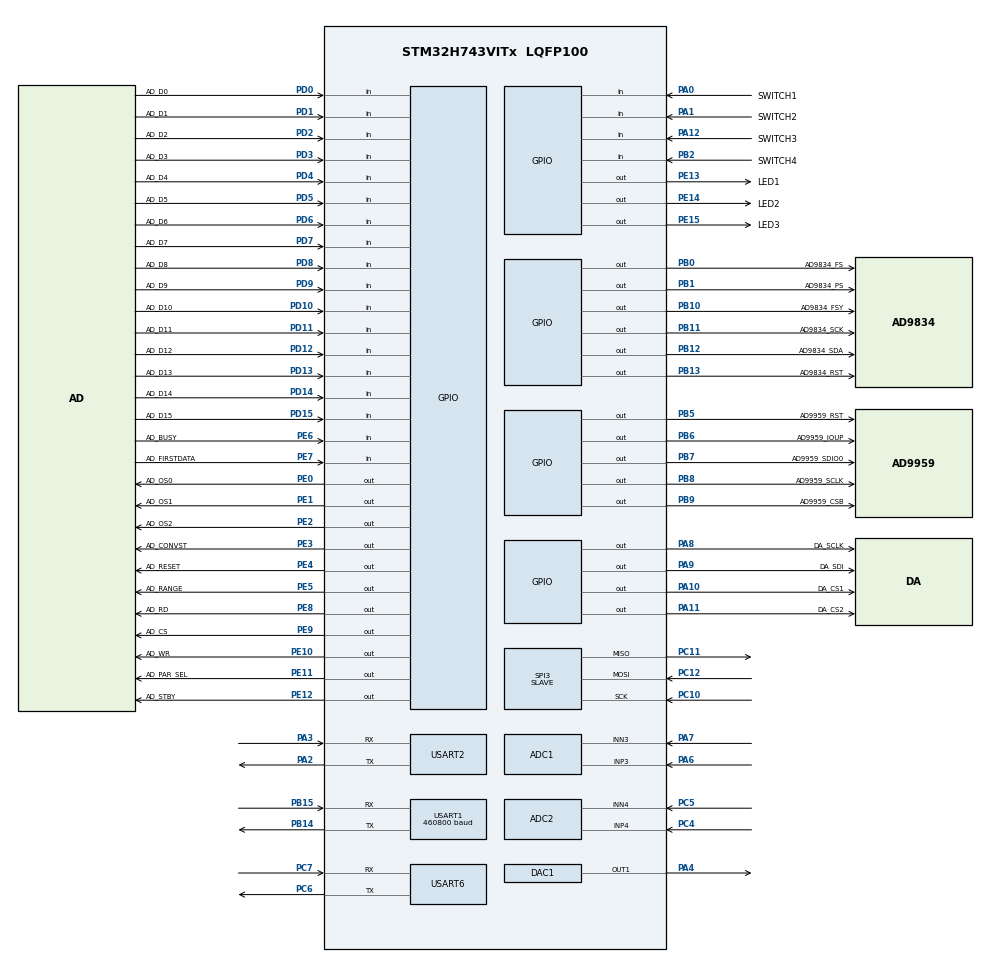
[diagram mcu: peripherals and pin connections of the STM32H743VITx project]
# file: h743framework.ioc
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ADC1.Channel-0\#ChannelRegularConversion=ADC_CHANNEL_3
ADC1.ClockPrescaler=ADC_CLOCK_ASYNC_DIV2
ADC1.NbrOfConversionFlag=1
ADC1.OffsetNumber-0\#ChannelRegularConversion=ADC_OFFSET_NONE
ADC1.OffsetSignedSaturation-0\#ChannelRegularConversion=DISABLE
ADC1.Rank-0\#ChannelRegularConversion=1
ADC1.SamplingTime-0\#ChannelRegularConversion=ADC_SAMPLETIME_1CYCLE_5
ADC1.SingleDiff-0\#ChannelRegularConversion=ADC_DIFFERENTIAL_ENDED
ADC1.master=1
ADC2.Channel-0\#ChannelRegularConversion=ADC_CHANNEL_4
ADC2.ClockPrescaler=ADC_CLOCK_ASYNC_DIV2
ADC2.NbrOfConversionFlag=1
ADC2.OffsetNumber-0\#ChannelRegularConversion=ADC_OFFSET_NONE
ADC2.OffsetSignedSaturation-0\#ChannelRegularConversion=DISABLE
ADC2.Rank-0\#ChannelRegularConversion=1
ADC2.SamplingTime-0\#ChannelRegularConversion=ADC_SAMPLETIME_1CYCLE_5
ADC2.SingleDiff-0\#ChannelRegularConversion=ADC_DIFFERENTIAL_ENDED
CORTEX_M7.CPU_DCache=Enabled
CORTEX_M7.CPU_ICache=Enabled
DAC1.DAC_Channel-DAC_OUT1=DAC_CHANNEL_1
Dma.Request0=SPI3_RX
Dma.SPI3_RX.0.Direction=DMA_PERIPH_TO_MEMORY
Dma.SPI3_RX.0.EventEnable=DISABLE
Dma.SPI3_RX.0.FIFOMode=DMA_FIFOMODE_DISABLE
Dma.SPI3_RX.0.Instance=DMA1_Stream0
Dma.SPI3_RX.0.MemDataAlignment=DMA_MDATAALIGN_HALFWORD
Dma.SPI3_RX.0.MemInc=DMA_MINC_ENABLE
Dma.SPI3_RX.0.Mode=DMA_CIRCULAR
Dma.SPI3_RX.0.PeriphDataAlignment=DMA_PDATAALIGN_HALFWORD
Dma.SPI3_RX.0.PeriphInc=DMA_PINC_DISABLE
Dma.SPI3_RX.0.Polarity=HAL_DMAMUX_REQ_GEN_RISING
Dma.SPI3_RX.0.Priority=DMA_PRIORITY_LOW
Dma.SPI3_RX.0.RequestNumber=1
Dma.SPI3_RX.0.SignalID=NONE
Dma.SPI3_RX.0.SyncEnable=DISABLE
Dma.SPI3_RX.0.SyncPolarity=HAL_DMAMUX_SYNC_NO_EVENT
Dma.SPI3_RX.0.SyncRequestNumber=1
Dma.SPI3_RX.0.SyncSignalID=NONE
Mcu.Family=STM32H7
Mcu.Name=STM32H743VITx
Mcu.Package=LQFP100
NVIC.DMA1_Stream0_IRQn=true\:0\:0\:false\:false\:true\:false\:true\:true
NVIC.PriorityGroup=NVIC_PRIORITYGROUP_4
NVIC.SPI3_IRQn=true\:0\:0\:false\:false\:true\:false\:true\:true
NVIC.TIM3_IRQn=true\:0\:0\:false\:false\:true\:true\:true\:true
NVIC.TIM4_IRQn=true\:0\:0\:false\:false\:true\:true\:true\:true
NVIC.TIM5_IRQn=true\:0\:0\:false\:false\:true\:true\:true\:true
NVIC.TIM6_DAC_IRQn=true\:0\:0\:false\:false\:true\:true\:true\:true
NVIC.TIM7_IRQn=true\:0\:0\:false\:false\:true\:true\:true\:true
NVIC.USART1_IRQn=true\:0\:0\:false\:false\:true\:true\:true\:true
NVIC.USART2_IRQn=true\:0\:0\:false\:false\:true\:true\:true\:true
NVIC.USART6_IRQn=true\:0\:0\:false\:false\:true\:true\:true\:true
PA0.GPIO_Label=SWITCH1
PA0.Signal=GPIO_Input
PA1.GPIO_Label=SWITCH2
PA1.Signal=GPIO_Input
PA10.GPIO_Label=DA_CS1
PA10.GPIO_Speed=GPIO_SPEED_FREQ_HIGH
PA10.Signal=GPIO_Output
PA11.GPIO_Label=DA_CS2
PA11.GPIO_Speed=GPIO_SPEED_FREQ_HIGH
PA11.Signal=GPIO_Output
PA12.GPIO_Label=SWITCH3
PA12.Signal=GPIO_Input
PA13\ (JTMS/SWDIO).Mode=JTAG_5_pins
PA13\ (JTMS/SWDIO).Signal=DEBUG_JTMS-SWDIO
PA14\ (JTCK/SWCLK).Mode=JTAG_5_pins
PA14\ (JTCK/SWCLK).Signal=DEBUG_JTCK-SWCLK
PA15\ (JTDI).Mode=JTAG_5_pins
PA15\ (JTDI).Signal=DEBUG_JTDI
PA2.Mode=Asynchronous
PA2.Signal=USART2_TX
PA3.Mode=Asynchronous
PA3.Signal=USART2_RX
PA4.Signal=COMP_DAC11_group
PA5.Signal=S_TIM2_CH1_ETR
PA6.Signal=ADCx_INP3
PA7.Signal=ADCx_INN3
PA8.GPIO_Label=DA_SCLK
PA8.GPIO_Speed=GPIO_SPEED_FREQ_HIGH
PA8.Signal=GPIO_Output
PA9.GPIO_Label=DA_SDI
PA9.GPIO_Speed=GPIO_SPEED_FREQ_HIGH
PA9.Signal=GPIO_Output
PB0.GPIO_Label=AD9834_FS
PB0.GPIO_Speed=GPIO_SPEED_FREQ_HIGH
PB0.Signal=GPIO_Output
PB1.GPIO_Label=AD9834_PS
PB1.GPIO_Speed=GPIO_SPEED_FREQ_HIGH
PB1.Signal=GPIO_Output
PB10.GPIO_Label=AD9834_FSY
PB10.GPIO_Speed=GPIO_SPEED_FREQ_HIGH
PB10.Signal=GPIO_Output
PB11.GPIO_Label=AD9834_SCK
PB11.GPIO_Speed=GPIO_SPEED_FREQ_HIGH
PB11.Signal=GPIO_Output
PB12.GPIO_Label=AD9834_SDA
PB12.GPIO_Speed=GPIO_SPEED_FREQ_HIGH
PB12.Signal=GPIO_Output
PB13.GPIO_Label=AD9834_RST
PB13.GPIO_Speed=GPIO_SPEED_FREQ_HIGH
PB13.Signal=GPIO_Output
PB14.Mode=Asynchronous
PB14.Signal=USART1_TX
PB15.Mode=Asynchronous
PB15.Signal=USART1_RX
PB2.GPIO_Label=SWITCH4
PB2.Signal=GPIO_Input
PB3\ (JTDO/TRACESWO).Mode=JTAG_5_pins
PB3\ (JTDO/TRACESWO).Signal=DEBUG_JTDO-SWO
PB4\ (NJTRST).Mode=JTAG_5_pins
PB4\ (NJTRST).Signal=DEBUG_JTRST
PB5.GPIO_Label=AD9959_RST
PB5.GPIO_Speed=GPIO_SPEED_FREQ_HIGH
PB5.Signal=GPIO_Output
PB6.GPIO_Label=AD9959_IOUP
PB6.GPIO_Speed=GPIO_SPEED_FREQ_HIGH
PB6.Signal=GPIO_Output
PB7.GPIO_Label=AD9959_SDIO0
PB7.GPIO_Speed=GPIO_SPEED_FREQ_HIGH
PB7.Signal=GPIO_Output
PB8.GPIO_Label=AD9959_SCLK
PB8.GPIO_Speed=GPIO_SPEED_FREQ_HIGH
PB8.Signal=GPIO_Output
PB9.GPIO_Label=AD9959_CSB
PB9.GPIO_Speed=GPIO_SPEED_FREQ_HIGH
PB9.Signal=GPIO_Output
PC10.Mode=Full_Duplex_Slave
PC10.Signal=SPI3_SCK
PC11.Mode=Full_Duplex_Slave
PC11.Signal=SPI3_MISO
PC12.Mode=Full_Duplex_Slave
PC12.Signal=SPI3_MOSI
PC4.Signal=ADCx_INP4
PC5.Signal=ADCx_INN4
PC6.Mode=Asynchronous
PC6.Signal=USART6_TX
PC7.Mode=Asynchronous
PC7.Signal=USART6_RX
PD0.GPIO_Label=AD_D0
PD0.Signal=GPIO_Input
PD1.GPIO_Label=AD_D1
PD1.Signal=GPIO_Input
PD10.GPIO_Label=AD_D10
PD10.Signal=GPIO_Input
PD11.GPIO_Label=AD_D11
PD11.Signal=GPIO_Input
PD12.GPIO_Label=AD_D12
PD12.Signal=GPIO_Input
PD13.GPIO_Label=AD_D13
PD13.Signal=GPIO_Input
PD14.GPIO_Label=AD_D14
PD14.Signal=GPIO_Input
PD15.GPIO_Label=AD_D15
PD15.Signal=GPIO_Input
PD2.GPIO_Label=AD_D2
PD2.Signal=GPIO_Input
PD3.GPIO_Label=AD_D3
PD3.Signal=GPIO_Input
PD4.GPIO_Label=AD_D4
PD4.Signal=GPIO_Input
PD5.GPIO_Label=AD_D5
PD5.Signal=GPIO_Input
PD6.GPIO_Label=AD_D6
PD6.Signal=GPIO_Input
PD7.GPIO_Label=AD_D7
PD7.Signal=GPIO_Input
PD8.GPIO_Label=AD_D8
PD8.Signal=GPIO_Input
PD9.GPIO_Label=AD_D9
PD9.Signal=GPIO_Input
PE0.GPIO_Label=AD_OS0
PE0.GPIO_Speed=GPIO_SPEED_FREQ_LOW
PE0.Signal=GPIO_Output
PE1.GPIO_Label=AD_OS1
PE1.GPIO_Speed=GPIO_SPEED_FREQ_LOW
PE1.Signal=GPIO_Output
PE10.GPIO_Label=AD_WR
PE10.GPIO_Speed=GPIO_SPEED_FREQ_HIGH
PE10.Signal=GPIO_Output
PE11.GPIO_Label=AD_PAR_SEL
PE11.GPIO_Speed=GPIO_SPEED_FREQ_LOW
PE11.Signal=GPIO_Output
PE12.GPIO_Label=AD_STBY
PE12.GPIO_Speed=GPIO_SPEED_FREQ_LOW
PE12.Signal=GPIO_Output
PE13.GPIO_Label=LED1
PE13.Signal=GPIO_Output
PE14.GPIO_Label=LED2
PE14.Signal=GPIO_Output
PE15.GPIO_Label=LED3
PE15.Signal=GPIO_Output
PE2.GPIO_Label=AD_OS2
PE2.GPIO_Speed=GPIO_SPEED_FREQ_LOW
PE2.Signal=GPIO_Output
PE3.GPIO_Label=AD_CONVST
PE3.GPIO_Speed=GPIO_SPEED_FREQ_HIGH
PE3.Signal=GPIO_Output
PE4.GPIO_Label=AD_RESET
PE4.GPIO_Speed=GPIO_SPEED_FREQ_HIGH
PE4.Signal=GPIO_Output
PE5.GPIO_Label=AD_RANGE
PE5.GPIO_Speed=GPIO_SPEED_FREQ_HIGH
PE5.Signal=GPIO_Output
PE6.GPIO_Label=AD_BUSY
PE6.Signal=GPIO_Input
PE7.GPIO_Label=AD_FIRSTDATA
PE7.Signal=GPIO_Input
PE8.GPIO_Label=AD_RD
PE8.GPIO_Speed=GPIO_SPEED_FREQ_HIGH
PE8.Signal=GPIO_Output
PE9.GPIO_Label=AD_CS
PE9.GPIO_Speed=GPIO_SPEED_FREQ_HIGH
PE9.Signal=GPIO_Output
PH0-OSC_IN\ (PH0).Mode=HSE-External-Oscillator
PH0-OSC_IN\ (PH0).Signal=RCC_OSC_IN
PH1-OSC_OUT\ (PH1).Mode=HSE-External-Oscillator
PH1-OSC_OUT\ (PH1).Signal=RCC_OSC_OUT
ProjectManager.HeapSize=0x200
ProjectManager.StackSize=0x400
ProjectManager.TargetToolchain=Makefile
RCC.ADCFreq_Value=40000000
RCC.APB1Freq_Value=32000000
RCC.APB2Freq_Value=32000000
RCC.APB3Freq_Value=32000000
RCC.APB4Freq_Value=32000000
RCC.CortexFreq_Value=32000000
RCC.D1CPRE=RCC_SYSCLK_DIV2
RCC.DIVM1=2
RCC.DIVM2=2
RCC.DIVN1=20
RCC.DIVN2=25
RCC.DIVP2=5
RCC.DIVQ1=4
RCC.DIVQ2=5
RCC.HCLKFreq_Value=32000000
RCC.HSE_VALUE=16000000
RCC.PLL2FRACN=0
RCC.PLL3FRACN=0
RCC.PLLFRACN=0
RCC.PLLSourceVirtual=RCC_PLLSOURCE_HSE
RCC.SYSCLKFreq_VALUE=64000000
RCC.USART16CLockSelection=RCC_USART16CLKSOURCE_PLL2
RCC.USART234578CLockSelection=RCC_USART234578CLKSOURCE_PLL2
RCC.USBFreq_Value=40000000
SH.ADCx_INN3.0=ADC1_INN3,IN3-Differential
SH.ADCx_INN4.0=ADC2_INN4,IN4-Differential
SH.ADCx_INP3.0=ADC1_INP3,IN3-Differential
SH.ADCx_INP4.0=ADC2_INP4,IN4-Differential
SH.COMP_DAC11_group.0=DAC1_OUT1,DAC_OUT1
SH.S_TIM2_CH1_ETR.0=TIM2_ETR
SPI3.DataSize=SPI_DATASIZE_16BIT
SPI3.Direction=SPI_DIRECTION_2LINES
SPI3.Mode=SPI_MODE_SLAVE
SPI3.VirtualType=VM_SLAVE
TIM3.AutoReloadPreload=TIM_AUTORELOAD_PRELOAD_ENABLE
TIM3.CounterMode=TIM_COUNTERMODE_DOWN
TIM3.Prescaler=99
TIM4.AutoReloadPreload=TIM_AUTORELOAD_PRELOAD_ENABLE
TIM4.CounterMode=TIM_COUNTERMODE_DOWN
TIM4.Period=4999
TIM4.Prescaler=199
TIM6.AutoReloadPreload=TIM_AUTORELOAD_PRELOAD_ENABLE
TIM6.Prescaler=199
TIM7.Prescaler=999
USART1.BaudRate=460800
USART1.OverSampling=UART_OVERSAMPLING_8
USART1.VirtualMode-Asynchronous=VM_ASYNC
USART2.VirtualMode-Asynchronous=VM_ASYNC
USART6.VirtualMode=VM_ASYNC
VP_TIM2_VS_ClockSourceINT.Mode=Internal
VP_TIM3_VS_ClockSourceINT.Mode=Internal
VP_TIM4_VS_ClockSourceINT.Mode=Internal
VP_TIM5_VS_ClockSourceINT.Mode=Internal
VP_TIM6_VS_ClockSourceINT.Mode=Enable_Timer
VP_TIM7_VS_ClockSourceINT.Mode=Enable_Timer
board=custom

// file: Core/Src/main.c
/* USER CODE BEGIN Header */
/**
 ******************************************************************************
 * @file           : main.c
 * @brief          : Main program body
 ******************************************************************************
 * @attention
 *
 * Copyright (c) 2023 STMicroelectronics.
 * All rights reserved.
 *
 * This software is licensed under terms that can be found in the LICENSE file
 * in the root directory of this software component.
 * If no LICENSE file comes with this software, it is provided AS-IS.
 *
 ******************************************************************************
 */
/* USER CODE END Header */
#include "main.h"
#include "adc.h"
#include "dac.h"
#include "dma.h"
#include "spi.h"
#include "tim.h"
#include "usart.h"
#include "gpio.h"

/* USER CODE BEGIN Includes */
#include <stdio.h>

#include "app.h"
#include "power.h"
#include "led.h"
/* USER CODE END Includes */

void SystemClock_Config(void);
void PeriphCommonClock_Config(void);

int main(void)
{

  /* Enable I-Cache---------------------------------------------------------*/
  SCB_EnableICache();

  /* Enable D-Cache---------------------------------------------------------*/
  SCB_EnableDCache();

  /* MCU Configuration--------------------------------------------------------*/

  /* Reset of all peripherals, Initializes the Flash interface and the Systick. */
  HAL_Init();

  /* Configure the system clock */
  SystemClock_Config();

/* Configure the peripherals common clocks */
  PeriphCommonClock_Config();

  /* Initialize all configured peripherals */
  MX_GPIO_Init();
  MX_DMA_Init();
  MX_ADC2_Init();
  MX_DAC1_Init();
  MX_TIM2_Init();
  MX_TIM3_Init();
  MX_USART1_UART_Init();
  MX_USART2_UART_Init();
  MX_USART6_UART_Init();
  MX_SPI3_Init();
  MX_ADC1_Init();
  MX_TIM4_Init();
  MX_TIM6_Init();
  MX_TIM5_Init();
  MX_TIM7_Init();
  /* USER CODE BEGIN 2 */
  LED_Init();
  APP_Init();
  /* USER CODE END 2 */

  /* Infinite loop */
  while (1) {

    /* USER CODE BEGIN 3 */
    APP_Loop();
  }
  /* USER CODE END 3 */
}

void SystemClock_Config(void)
{
  RCC_OscInitTypeDef RCC_OscInitStruct = {0};
  RCC_ClkInitTypeDef RCC_ClkInitStruct = {0};

  /** Supply configuration update enable
  */
  HAL_PWREx_ConfigSupply(PWR_LDO_SUPPLY);

  /** Configure the main internal regulator output voltage
  */
  __HAL_PWR_VOLTAGESCALING_CONFIG(PWR_REGULATOR_VOLTAGE_SCALE3);

  while(!__HAL_PWR_GET_FLAG(PWR_FLAG_VOSRDY)) {}

  /** Initializes the RCC Oscillators according to the specified parameters
  * in the RCC_OscInitTypeDef structure.
  */
  RCC_OscInitStruct.OscillatorType = RCC_OSCILLATORTYPE_HSI|RCC_OSCILLATORTYPE_HSE;
  RCC_OscInitStruct.HSEState = RCC_HSE_ON;
  RCC_OscInitStruct.HSIState = RCC_HSI_DIV1;
  RCC_OscInitStruct.HSICalibrationValue = RCC_HSICALIBRATION_DEFAULT;
  RCC_OscInitStruct.PLL.PLLState = RCC_PLL_ON;
  RCC_OscInitStruct.PLL.PLLSource = RCC_PLLSOURCE_HSE;
  RCC_OscInitStruct.PLL.PLLM = 2;
  RCC_OscInitStruct.PLL.PLLN = 20;
  RCC_OscInitStruct.PLL.PLLP = 2;
  RCC_OscInitStruct.PLL.PLLQ = 4;
  RCC_OscInitStruct.PLL.PLLR = 2;
  RCC_OscInitStruct.PLL.PLLRGE = RCC_PLL1VCIRANGE_3;
  RCC_OscInitStruct.PLL.PLLVCOSEL = RCC_PLL1VCOMEDIUM;
  RCC_OscInitStruct.PLL.PLLFRACN = 0;
  if (HAL_RCC_OscConfig(&RCC_OscInitStruct) != HAL_OK)
  {
    Error_Handler();
  }

  /** Initializes the CPU, AHB and APB buses clocks
  */
  RCC_ClkInitStruct.ClockType = RCC_CLOCKTYPE_HCLK|RCC_CLOCKTYPE_SYSCLK
                              |RCC_CLOCKTYPE_PCLK1|RCC_CLOCKTYPE_PCLK2
                              |RCC_CLOCKTYPE_D3PCLK1|RCC_CLOCKTYPE_D1PCLK1;
  RCC_ClkInitStruct.SYSCLKSource = RCC_SYSCLKSOURCE_HSI;
  RCC_ClkInitStruct.SYSCLKDivider = RCC_SYSCLK_DIV2;
  RCC_ClkInitStruct.AHBCLKDivider = RCC_HCLK_DIV1;
  RCC_ClkInitStruct.APB3CLKDivider = RCC_APB3_DIV1;
  RCC_ClkInitStruct.APB1CLKDivider = RCC_APB1_DIV1;
  RCC_ClkInitStruct.APB2CLKDivider = RCC_APB2_DIV1;
  RCC_ClkInitStruct.APB4CLKDivider = RCC_APB4_DIV1;

  if (HAL_RCC_ClockConfig(&RCC_ClkInitStruct, FLASH_LATENCY_0) != HAL_OK)
  {
    Error_Handler();
  }
}

void PeriphCommonClock_Config(void)
{
  RCC_PeriphCLKInitTypeDef PeriphClkInitStruct = {0};

  /** Initializes the peripherals clock
  */
  PeriphClkInitStruct.PeriphClockSelection = RCC_PERIPHCLK_ADC|RCC_PERIPHCLK_USART1
                              |RCC_PERIPHCLK_USART6|RCC_PERIPHCLK_USART2;
  PeriphClkInitStruct.PLL2.PLL2M = 2;
  PeriphClkInitStruct.PLL2.PLL2N = 25;
  PeriphClkInitStruct.PLL2.PLL2P = 5;
  PeriphClkInitStruct.PLL2.PLL2Q = 5;
  PeriphClkInitStruct.PLL2.PLL2R = 2;
  PeriphClkInitStruct.PLL2.PLL2RGE = RCC_PLL2VCIRANGE_3;
  PeriphClkInitStruct.PLL2.PLL2VCOSEL = RCC_PLL2VCOWIDE;
  PeriphClkInitStruct.PLL2.PLL2FRACN = 0;
  PeriphClkInitStruct.Usart234578ClockSelection = RCC_USART234578CLKSOURCE_PLL2;
  PeriphClkInitStruct.Usart16ClockSelection = RCC_USART16CLKSOURCE_PLL2;
  PeriphClkInitStruct.AdcClockSelection = RCC_ADCCLKSOURCE_PLL2;
  if (HAL_RCCEx_PeriphCLKConfig(&PeriphClkInitStruct) != HAL_OK)
  {
    Error_Handler();
  }
}

void Error_Handler(void)
{
  /* USER CODE BEGIN Error_Handler_Debug */
  /* User can add his own implementation to report the HAL error return state */
  __disable_irq();
  LED_On(1);
  printf("HAL ERROR\n");
  while (1) {
  }
  /* USER CODE END Error_Handler_Debug */
}

#ifdef  USE_FULL_ASSERT
/**
  * @brief  Reports the name of the source file and the source line number
  *         where the assert_param error has occurred.
  * @param  file: pointer to the source file name
  * @param  line: assert_param error line source number
  * @retval None
  */
void assert_failed(uint8_t *file, uint32_t line)
{
  /* USER CODE BEGIN 6 */
  /* User can add his own implementation to report the file name and line
     number, ex: printf("Wrong parameters value: file %s on line %d\r\n", file,
     line) */
  /* USER CODE END 6 */
}
#endif /* USE_FULL_ASSERT */
